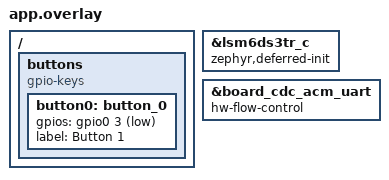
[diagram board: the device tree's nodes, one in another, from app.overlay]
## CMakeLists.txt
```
cmake_minimum_required(VERSION 3.20.0)
find_package(Zephyr REQUIRED HINTS $ENV{ZEPHYR_BASE})
project(firmware)

FILE(GLOB app_sources src/*.c)
list(FILTER app_sources EXCLUDE REGEX "/(hids_mouse|ble_gatt)\\.c$")
target_sources(app PRIVATE ${app_sources})

if(CONFIG_IM_BLE_DEVICE_MOUSE)
  target_sources(app PRIVATE src/hids_mouse.c)
endif()
if(CONFIG_IM_BLE_DEVICE_GATT)
  target_sources(app PRIVATE src/ble_gatt.c)
endif()
```

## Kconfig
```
menu "IMU Mouse"

choice IM_BLE_DEVICE
	prompt "BLE device"
	default IM_BLE_DEVICE_GATT
	help
	  Only the selected device is compiled, initialized and advertised.
config IM_BLE_DEVICE_GATT
	bool "IMU pose streaming (custom GATT service)"
config IM_BLE_DEVICE_MOUSE
	bool "HID mouse"
endchoice

choice IM_BUTTON_MODE
	prompt "Button 1 function"
	default IM_BUTTON_MODE_SENSITIVITY
	help
	  What button 1 does once the passkey pairing is not pending.
config IM_BUTTON_MODE_CLICK
	bool "Left mouse button (click and hold)"
config IM_BUTTON_MODE_SENSITIVITY
	bool "Cycle cursor sensitivity"
endchoice

config IM_IMU_SAMPLE_RATE_HZ
	int "imu update rate"
	range 52 416
	default 208
	help
		12, 26, 52, 104, 208, 416, 833, 1666, 3332 and 6664 Hz

config IM_IMU_SKIP_CALIBRATION_MOTION_CHECK
	bool "Debug: accept motion during startup gyro calibration"
		default n
	help
	  Development only. Calibration completes after a fixed sample count even if
	  the device moves (e.g. on a train); expect gyro bias drift.

config IM_IMU_PRINT_SAMPLE
	bool "Print each IMU sample"
	default n

config IM_IMU_PRINT_PERIODIC_STATS
	bool "Periodic IMU statistics"
	default n

config IM_IMU_STATS_PERIOD_MS
	int "IMU statistics period in milliseconds"
	depends on IM_IMU_PRINT_PERIODIC_STATS
	default 1000

config IM_BLE_GATT_PRINT_PERIODIC_STATS
	bool "Periodic BLE GATT statistics"
	depends on IM_BLE_DEVICE_GATT
	default n

config IM_BLE_GATT_STATS_PERIOD_MS
	int "BLE GATT statistics period in milliseconds"
	depends on IM_BLE_GATT_PRINT_PERIODIC_STATS
	default 1000
		
config SAMPLE_BT_HIDS_SECURITY
	bool "Bluetooth LE security"
	default y
	imply BT_PRIVACY
	select BT_SMP
	select BT_SETTINGS
	select FLASH
	select FLASH_PAGE_LAYOUT
	select FLASH_MAP
	select SETTINGS
	imply ZMS if (SOC_FLASH_NRF_RRAM || SOC_FLASH_NRF_MRAM)
	imply NVS if !(SOC_FLASH_NRF_RRAM || SOC_FLASH_NRF_MRAM)
	help
	  Enable Bluetooth LE security support.

config SAMPLE_BT_HIDS_SECURITY_MITM
	bool "Passkey display MITM protection"
	depends on SAMPLE_BT_HIDS_SECURITY
	depends on PRINTK
	default y
	help
	  Enable displaying passkey for Man-In-The-Middle (MITM) protection.
	  Implementation uses the "printk" function to display the passkey.

config SAMPLE_BT_DIRECTED_ADVERTISING
	bool "Directed advertising"
	default n
	depends on SAMPLE_BT_HIDS_SECURITY

endmenu

source "Kconfig.zephyr"
```

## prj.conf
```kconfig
# Logging subsystem
CONFIG_LOG=y
CONFIG_LOG_MODE_DEFERRED=y  # Log to RAM buffer
CONFIG_LOG_BUFFER_SIZE=4096
CONFIG_LOG_PROCESS_THREAD=n # Turn off log kernel thread

# USB CDC ACM - virtual serial port
CONFIG_USB_DEVICE_STACK=y

# Turn off the new USB stack
CONFIG_USB_DEVICE_STACK_NEXT=n
CONFIG_USBD_CDC_ACM_CLASS=n
CONFIG_USB_CDC_ACM_RINGBUF_SIZE=4096

# Device init logging
CONFIG_SENSOR_LOG_LEVEL_DBG=n
CONFIG_I2C_LOG_LEVEL_DBG=n

# Devices
CONFIG_I2C=y
CONFIG_SENSOR=y
CONFIG_SERIAL=y
CONFIG_UART_LINE_CTRL=y
CONFIG_LSM6DSL=y
CONFIG_LSM6DSL_TRIGGER_OWN_THREAD=y # Data-ready interrupt on irq-gpios

# Other
CONFIG_CBPRINTF_FP_SUPPORT=y

# Hardware FPU, threads using it need K_FP_REGS
CONFIG_FPU=y
CONFIG_FPU_SHARING=y

# Bluetooth setup below
CONFIG_BT=y
CONFIG_BT_MAX_CONN=1
CONFIG_BT_MAX_PAIRED=2
CONFIG_BT_ATT_TX_COUNT=16
CONFIG_BT_L2CAP_TX_BUF_COUNT=16
CONFIG_BT_BUF_ACL_TX_COUNT=16
CONFIG_BT_BUF_EVT_RX_COUNT=20
CONFIG_BT_PERIPHERAL=y
CONFIG_BT_DEVICE_NAME="IMU Sandbox"
CONFIG_BT_DEVICE_APPEARANCE=962
CONFIG_BT_L2CAP_TX_MTU=128
CONFIG_BT_BUF_ACL_TX_SIZE=70
CONFIG_BT_BUF_ACL_RX_SIZE=70

CONFIG_NCS_SAMPLES_DEFAULTS=y

# Disable automatic initiation of PHY updates and the SMP Security Requests.
# Workaround to prevent disconnection with the following disconnect reasons:
# - 0x08 (BT_HCI_ERR_CONN_TIMEOUT)
# - 0x13 (BT_HCI_ERR_REMOTE_USER_TERM_CONN)
# - 0x23 (BT_HCI_ERR_LL_PROC_COLLISION)
# - 0x2A (BT_HCI_ERR_DIFF_TRANS_COLLISION)
# Some laptop Bluetooth controllers may simultaneously trigger two Link Layer
# procedures which results in a procedure collision and disconnection.
CONFIG_BT_GATT_AUTO_SEC_REQ=n
CONFIG_BT_AUTO_PHY_UPDATE=n

CONFIG_BT_BAS=y
CONFIG_BT_HIDS=y
CONFIG_BT_HIDS_INPUT_REP_MAX=3
CONFIG_BT_HIDS_OUTPUT_REP_MAX=0
CONFIG_BT_HIDS_FEATURE_REP_MAX=0
CONFIG_BT_HIDS_ATTR_MAX=24
CONFIG_BT_HIDS_MAX_CLIENT_COUNT=1
CONFIG_BT_HIDS_DEFAULT_PERM_RW_ENCRYPT=y
CONFIG_BT_GATT_UUID16_POOL_SIZE=40
CONFIG_BT_GATT_CHRC_POOL_SIZE=20

CONFIG_BT_CONN_CTX=y

CONFIG_BT_DIS=y
CONFIG_BT_DIS_MANUF_NAME=y
CONFIG_BT_DIS_MANUF_NAME_STR="NordicSemiconductor"
CONFIG_BT_DIS_PNP=y
CONFIG_BT_DIS_PNP_VID_SRC=2
CONFIG_BT_DIS_PNP_VID=0x1915
CONFIG_BT_DIS_PNP_PID=0xEEEE
CONFIG_BT_DIS_PNP_VER=0x0100

# Increase BT TX processor thread stack size to prevent stack overflow when performing directed
# advertising. On nRF52840 the maximum measured stack usage is 780 bytes. On nRF54L15 the maximum
# measured stack usage is 856 bytes.
CONFIG_BT_TX_PROCESSOR_STACK_SIZE=1024

CONFIG_MAIN_STACK_SIZE=2048
CONFIG_SYSTEM_WORKQUEUE_STACK_SIZE=2048

# Delay the GATT/ATT "sent" callback until the controller has actually transmitted the PDU,
# instead of firing it as soon as the buffer is handed to L2CAP/HCI.
# The movement in-flight limit in hids_mouse.c relies on this.
CONFIG_BT_ATT_SENT_CB_AFTER_TX=y
```

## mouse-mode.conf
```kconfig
CONFIG_IM_BLE_DEVICE_MOUSE=y
```

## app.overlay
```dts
&lsm6ds3tr_c {
	// Skip boot-time init (timing issue):
	// 	<dbg> LSM6DSL: lsm6dsl_init_chip: failed to reboot device
	// 	<err> LSM6DSL: Failed to initialize chip
	// im_imu_init() calls device_init() later
	zephyr,deferred-init;
};

&board_cdc_acm_uart {
	// Without it poll_out drops data when the 1 KB TX ring buffer is full, losing early logs
	hw-flow-control;
};

#include <zephyr/dt-bindings/gpio/gpio.h>

/ {
    buttons {
        compatible = "gpio-keys";

        button0: button_0 {
            gpios = <&gpio0 3 (GPIO_PULL_UP | GPIO_ACTIVE_LOW)>;  // Button D1 of the Seeed Studio XIAO Expansion Board
            label = "Button 1";
        };
    };
};
```

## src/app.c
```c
#include <stdio.h>
#include <math.h>
#include <zephyr/kernel.h>

#include "state.h"
#include "imu.h"
#include "fusion.h"
#include "gpio.h"

#if defined(CONFIG_IM_BLE_DEVICE_MOUSE)
#include "hids_mouse.h"

// Integers on purpose: level 2 (2500) is the default
static const int s_px_per_rad[] = {1500, 2000, 2500, 3000, 3500, 4000, 4500, 5000, 5500};
static uint8_t s_sens_idx = 2;
// Mounting-dependent: yaw (gyro Z) -> X, pitch (gyro Y) -> Y; roll (gyro X) is ignored
#define MOUSE_X_SIGN (-1.0f)
#define MOUSE_Y_SIGN (-1.0f) // Cable to front
#define MOUSE_DEADZONE_RAD_S 0.02f

// Sub-pixel remainders carried between samples
static float s_mouse_rem_x;
static float s_mouse_rem_y;

// A press that confirmed pairing must not produce a click release
static bool s_press_used_for_pairing;
#elif defined(CONFIG_IM_BLE_DEVICE_GATT)
#include "ble_gatt.h"
#endif

static atomic_t s_streaming_active;

void im_app_on_error(void)
{
	im_state_set(IM_APP_STATE_FAIL);
}

void im_app_on_ble_session(bool ready)
{
	const atomic_val_t new_state = ready ? 1 : 0;
	const atomic_val_t old_state = atomic_set(&s_streaming_active, new_state);
	if (old_state == new_state)
	{
		return;
	}
	im_state_set(ready ? IM_APP_STATE_CALIBRATING : IM_APP_STATE_WAITING);
	im_imu_set_streaming(ready);
}

void im_app_on_button(bool pressed)
{
#if defined(CONFIG_IM_BLE_DEVICE_MOUSE)
	if (pressed && im_hids_mouse_pairing_pending())
	{
		s_press_used_for_pairing = true;
		im_hids_mouse_pairing_reply(true);
		return;
	}
	if (!pressed && s_press_used_for_pairing)
	{
		s_press_used_for_pairing = false;
		return;
	}
	if (IS_ENABLED(CONFIG_IM_BUTTON_MODE_SENSITIVITY))
	{
		if (pressed)
		{
			s_sens_idx = (s_sens_idx + 1) % ARRAY_SIZE(s_px_per_rad);
			printk("Sensitivity: %d px/rad\n", s_px_per_rad[s_sens_idx]);
		}
	}
	else if(IS_ENABLED(CONFIG_IM_BUTTON_MODE_CLICK))
	{
		im_hids_mouse_button(pressed);
	}
#elif defined(CONFIG_IM_BLE_DEVICE_GATT)
	ARG_UNUSED(pressed);
#endif
}

void im_app_on_imu_sample(im_vec3 gyro_rate, im_vec3 acceleration, float dt_s)
{
	enum im_app_state state = im_state_get();
	if (state != IM_APP_STATE_CALIBRATING && state != IM_APP_STATE_RUNNING)
	{
		return;
	}

	struct im_fusion_rates rates;
	const bool fusion_valid = im_fusion_update(gyro_rate, acceleration, dt_s, &rates);
	if (!fusion_valid)
	{
		return;
	}
	if (state == IM_APP_STATE_CALIBRATING)
	{
		im_state_set(IM_APP_STATE_RUNNING);
	}

#if defined(CONFIG_IM_BLE_DEVICE_MOUSE)
	const float px_per_rad = (float)s_px_per_rad[s_sens_idx];
	const bool x_active = fabsf(rates.yaw) >= MOUSE_DEADZONE_RAD_S;
	const bool y_active = fabsf(rates.pitch) >= MOUSE_DEADZONE_RAD_S;
	const float fx = x_active
		? s_mouse_rem_x + MOUSE_X_SIGN * rates.yaw * px_per_rad * dt_s
		: 0.0f;
	const float fy = y_active
		? s_mouse_rem_y + MOUSE_Y_SIGN * rates.pitch * px_per_rad * dt_s
		: 0.0f;
	const int16_t dx = (int16_t)fx;
	const int16_t dy = (int16_t)fy;
	s_mouse_rem_x = x_active ? fx - dx : 0.0f;
	s_mouse_rem_y = y_active ? fy - dy : 0.0f;
	if (dx || dy)
	{
		im_hids_mouse_move(dx, dy);
	}
#elif defined(CONFIG_IM_BLE_DEVICE_GATT)
	im_ble_gatt_push_frame(rates.orientation, acceleration);
#endif
}
```

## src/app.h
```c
#ifndef IM_APP_H
#define IM_APP_H

#include <stdbool.h>
#include "math3d.h"

// Application events
void im_app_on_imu_sample(im_vec3 gyro_rate, im_vec3 acceleration, float dt_s);
void im_app_on_error(void);
void im_app_on_ble_session(bool ready);
void im_app_on_button(bool pressed);

#endif
```

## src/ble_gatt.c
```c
#include <math.h>
#include <stdint.h>
#include <errno.h>
#include <string.h>

#include <zephyr/kernel.h>
#include <zephyr/sys/byteorder.h>
#include <zephyr/sys/printk.h>
#include <zephyr/bluetooth/bluetooth.h>
#include <zephyr/bluetooth/gatt.h>
#include <zephyr/bluetooth/uuid.h>
#include <zephyr/settings/settings.h>

#include "ble_gatt.h"
#include "threads.h"

// Internal linkage

// Thread and synchronisation
static K_THREAD_STACK_DEFINE(s_ble_gatt_thread_stack, IM_BLE_GATT_THREAD_STACK_SIZE);
static struct k_thread s_ble_gatt_thread_data;
static K_SEM_DEFINE(s_pending_frame_ready, 0, 1);

// Latest encoded frame; a newer pose overwrites an unsent one
#define BLE_POSE_FRAME_SIZE 20
static bool s_pending;
static struct k_spinlock s_pending_lock;
static uint8_t s_pending_frame[BLE_POSE_FRAME_SIZE];
static uint16_t s_frame_sequence;
static bool s_link_connected;
static bool s_pose_notifications_enabled;
static volatile uint16_t s_connection_interval;
static im_ble_gatt_session_cb_t s_session_callback;

/* Connection intervals are expressed in 1.25 ms units. */
#define MIN_SEND_INTERVAL_UNITS 6
#define MAX_SEND_INTERVAL_UNITS 9

static void s_update_streaming(void)
{
	const bool fast_enough = s_connection_interval >= MIN_SEND_INTERVAL_UNITS && s_connection_interval <= MAX_SEND_INTERVAL_UNITS;
	const bool ready = s_link_connected && s_pose_notifications_enabled && fast_enough;
	if (!ready)
	{
		k_spinlock_key_t key = k_spin_lock(&s_pending_lock);
		s_pending = false;
		k_spin_unlock(&s_pending_lock, key);
	}
	if (s_session_callback)
	{
		s_session_callback(ready);
	}
}

// Diagnostics, printed once per second
static uint32_t s_stat_ok, s_stat_err, s_stat_max_us, s_stat_dropped, s_stat_gated;
static int s_stat_last_err;
#if CONFIG_IM_BLE_GATT_PRINT_PERIODIC_STATS
static int64_t s_stat_next_ms;
#endif

// Service definition
// UUIDs match simulator/src/ble/ble-client.ts and docs/ble.md.
#define BLE_SERVICE_UUID_BYTES 0x9e, 0xca, 0xcc, 0x24, 0x0e, 0xe5, 0xa9, 0xe0, 0x93, 0xf3, 0xa3, 0xb5, 0x01, 0x00, 0x40, 0x7e
#define BLE_POSE_UUID_BYTES 0x9e, 0xca, 0xcc, 0x24, 0x0e, 0xe5, 0xa9, 0xe0, 0x93, 0xf3, 0xa3, 0xb5, 0x02, 0x00, 0x40, 0x7e
#define BLE_INFO_UUID_BYTES 0x9e, 0xca, 0xcc, 0x24, 0x0e, 0xe5, 0xa9, 0xe0, 0x93, 0xf3, 0xa3, 0xb5, 0x03, 0x00, 0x40, 0x7e
static struct bt_uuid_128 s_service_uuid = BT_UUID_INIT_128(BLE_SERVICE_UUID_BYTES);
static struct bt_uuid_128 s_pose_uuid = BT_UUID_INIT_128(BLE_POSE_UUID_BYTES);
static struct bt_uuid_128 s_info_uuid = BT_UUID_INIT_128(BLE_INFO_UUID_BYTES);

static void s_pose_ccc_changed(const struct bt_gatt_attr *attr, uint16_t value)
{
	// Client Characteristic Configuration Descriptor (CCCD)
	// Notifications enabled means that a client subscribed to the service
	// This is only informational
	ARG_UNUSED(attr);
	s_pose_notifications_enabled = (value & BT_GATT_CCC_NOTIFY) != 0;
	s_update_streaming();
	if (s_pose_notifications_enabled)
	{
		printk("BLE GATT pose notifications enabled\n");
	}
	else
	{
		printk("BLE GATT pose notifications disabled\n");
	}
}
static ssize_t s_read_info(struct bt_conn *conn, const struct bt_gatt_attr *attr, void *buf, uint16_t len, uint16_t offset)
{
	ARG_UNUSED(attr);
	const uint8_t info[] = 
	{
		CONFIG_IM_IMU_SAMPLE_RATE_HZ & 0xff,
		(CONFIG_IM_IMU_SAMPLE_RATE_HZ >> 8) & 0xff,
	};
	return bt_gatt_attr_read(conn, attr, buf, len, offset, info, sizeof(info));
}
BT_GATT_SERVICE_DEFINE(ble_gatt_service,
	BT_GATT_PRIMARY_SERVICE(&s_service_uuid),
	BT_GATT_CHARACTERISTIC(&s_pose_uuid.uuid, BT_GATT_CHRC_NOTIFY, BT_GATT_PERM_NONE, NULL, NULL, NULL),
	BT_GATT_CCC(s_pose_ccc_changed, BT_GATT_PERM_READ | BT_GATT_PERM_WRITE),
	BT_GATT_CHARACTERISTIC(&s_info_uuid.uuid, BT_GATT_CHRC_READ, BT_GATT_PERM_READ, s_read_info, NULL, NULL),
);

// Advertisement
static struct k_work s_adv_work;
static const struct bt_data s_ad[] =
{
	BT_DATA_BYTES(BT_DATA_FLAGS, (BT_LE_AD_GENERAL | BT_LE_AD_NO_BREDR)),
	BT_DATA_BYTES(BT_DATA_UUID128_ALL, BLE_SERVICE_UUID_BYTES),
};
static const struct bt_data s_sd[] =
{
	BT_DATA(BT_DATA_NAME_COMPLETE, CONFIG_BT_DEVICE_NAME, sizeof(CONFIG_BT_DEVICE_NAME) - 1),
};
static void s_adv_process(struct k_work *work)
{
	ARG_UNUSED(work);
	const int err = bt_le_adv_start(BT_LE_ADV_CONN_FAST_2, s_ad, ARRAY_SIZE(s_ad), s_sd, ARRAY_SIZE(s_sd));
	if (err)
	{
		printk("ERROR: BLE GATT advertising failed to start (err %d)\n", err);
		return;
	}
	printk("BLE GATT advertising started\n");
}

// Connection lifecycle and timing
// Requested connection interval 7.5-11.25 ms, latency 0, 4s timeout.
#define FAST_CONN_PARAM BT_LE_CONN_PARAM(MIN_SEND_INTERVAL_UNITS, MAX_SEND_INTERVAL_UNITS, 0, 400)
static void s_connected(struct bt_conn *conn, uint8_t err)
{
	if (err)
	{
		s_link_connected = false;
		s_pose_notifications_enabled = false;
		s_update_streaming();
		printk("Error: BLE GATT connection failed (err 0x%02x)\n", err);
		k_work_submit(&s_adv_work);
		return;
	}
	s_link_connected = true;
	s_connection_interval = 0;
	// Reads the interval when connection starts
	// Interval is set by the central, peripherial can request different interval later
	struct bt_conn_info info;
	if (bt_conn_get_info(conn, &info) == 0)
	{
		s_connection_interval = info.le.interval;
		printk("BLE GATT connection begin: interval=%u\n", s_connection_interval);
	}
	s_update_streaming();
	const int param_err = bt_conn_le_param_update(conn, FAST_CONN_PARAM);
	if (param_err)
	{
		printk("Error: BLE GATT connection parameter update request failed (err %d)\n", param_err);
	}
}
static void s_disconnected(struct bt_conn *conn, uint8_t reason)
{
	ARG_UNUSED(conn);
	ARG_UNUSED(reason);
	s_link_connected = false;
	s_pose_notifications_enabled = false;
	s_connection_interval = 0;
	s_update_streaming();
	printk("BLE GATT connection end\n");
	k_work_submit(&s_adv_work);
}
static void s_le_param_updated(struct bt_conn *conn, uint16_t interval, uint16_t latency, uint16_t timeout)
{
	// This is called when the central accepts new interval values
	ARG_UNUSED(conn);
	printk("BLE GATT connection params: interval=%u (%u.%02u ms) latency=%u timeout=%u\n", interval, interval * 5 / 4, (interval * 125) % 100, latency, timeout);
	s_connection_interval = interval;
	s_update_streaming();
}
BT_CONN_CB_DEFINE(s_connection_cb) =
{
	.connected = s_connected,
	.disconnected = s_disconnected,
	.le_param_updated = s_le_param_updated,
};

static void s_ble_gatt_thread_fn(void *p1, void *p2, void *p3)
{
	ARG_UNUSED(p1);
	ARG_UNUSED(p2);
	ARG_UNUSED(p3);
	while (1)
	{
		k_sem_take(&s_pending_frame_ready, K_FOREVER);

		// Copy frame from pending buffer
		uint8_t frame[BLE_POSE_FRAME_SIZE];
		k_spinlock_key_t key = k_spin_lock(&s_pending_lock);
		const bool have = s_pending;
		if (have)
		{
			memcpy(frame, s_pending_frame, sizeof(frame));
			s_pending = false;
		}
		k_spin_unlock(&s_pending_lock, key);
		// Send the local frame
		if (have)
		{
			const uint32_t t0 = k_cycle_get_32();
			const int err = bt_gatt_notify(NULL, &ble_gatt_service.attrs[2], frame, sizeof(frame));
			const uint32_t dt_us = k_cyc_to_us_floor32(k_cycle_get_32() - t0);
			if (dt_us > s_stat_max_us)
			{
				s_stat_max_us = dt_us;
			}
			if (err == 0)
			{
				s_stat_ok++;
			}
			else if (err != -ENOTCONN)
			{
				s_stat_err++;
				s_stat_last_err = err;
			}
		}
#if CONFIG_IM_BLE_GATT_PRINT_PERIODIC_STATS
		const int64_t now_ms = k_uptime_get();
		if (have && now_ms >= s_stat_next_ms)
		{
			printk("BLE GATT notify: ok=%u err=%u (last %d) dropped=%u gated=%u max_call=%u us\n", s_stat_ok, s_stat_err, s_stat_last_err, s_stat_dropped, s_stat_gated, s_stat_max_us);
			s_stat_ok = s_stat_err = s_stat_max_us = s_stat_dropped = s_stat_gated = 0;
			s_stat_next_ms = now_ms + CONFIG_IM_BLE_GATT_STATS_PERIOD_MS;
		}
#endif
	}
}

static int16_t s_clamp_i16(float value)
{
	if (value > INT16_MAX)
	{
		return INT16_MAX;
	}
	if (value < INT16_MIN)
	{
		return INT16_MIN;
	}
	return (int16_t)lrintf(value);
}

// External linkage

bool im_ble_gatt_init(void)
{
	printk("BLE GATT initiating\n");
	const int err = bt_enable(NULL);
	if (err)
	{
		printk("BLE GATT init failed (err %d)\n", err);
		return false;
	}
	k_work_init(&s_adv_work, s_adv_process);
	if (IS_ENABLED(CONFIG_SETTINGS))
	{
		settings_load();
	}
	printk("BLE GATT initialized\n");
	return true;
}

void im_ble_gatt_set_session_callback(im_ble_gatt_session_cb_t callback)
{
	s_session_callback = callback;
	s_update_streaming();
}

bool im_ble_gatt_start(void)
{
	k_tid_t tid = k_thread_create(&s_ble_gatt_thread_data, s_ble_gatt_thread_stack,
					      K_THREAD_STACK_SIZEOF(s_ble_gatt_thread_stack),
					      s_ble_gatt_thread_fn, NULL, NULL, NULL,
					      IM_BLE_GATT_THREAD_PRIORITY, 0, K_NO_WAIT);
	if (!tid)
	{
		printk("Error: BLE GATT thread failed to start\n");
		return false;
	}
	k_thread_name_set(tid, "ble_gatt");
	k_work_submit(&s_adv_work);	// This begins the advertisement
	printk("BLE GATT started\n");
	return true;
}

bool im_ble_gatt_push_frame(im_quat orientation, im_vec3 acceleration)
{
	// Gate poses to honor the agreed interval
	const uint16_t interval = s_connection_interval;
	if (!s_link_connected || !s_pose_notifications_enabled || interval == 0 ||
	    interval > MAX_SEND_INTERVAL_UNITS)
	{
		s_stat_gated++;
		return false;
	}

	// Build the frame
	uint8_t frame[BLE_POSE_FRAME_SIZE] = {0};
	sys_put_le16(s_frame_sequence++, &frame[0]);
	sys_put_le32(k_uptime_get_32(), &frame[2]);
	sys_put_le16(s_clamp_i16(orientation.w * 16384.0f), &frame[6]);
	sys_put_le16(s_clamp_i16(orientation.x * 16384.0f), &frame[8]);
	sys_put_le16(s_clamp_i16(orientation.y * 16384.0f), &frame[10]);
	sys_put_le16(s_clamp_i16(orientation.z * 16384.0f), &frame[12]);
	// Acceleration is m/s^2 internally; the wire unit is 1 mg (0.001 g).
	sys_put_le16(s_clamp_i16(acceleration.x * 101.9716f), &frame[14]);
	sys_put_le16(s_clamp_i16(acceleration.y * 101.9716f), &frame[16]);
	sys_put_le16(s_clamp_i16(acceleration.z * 101.9716f), &frame[18]);

	// Signal the thread but only if it processed previous frame
	// Otherwise, update the pending frame - last frame will be sent
	k_spinlock_key_t key = k_spin_lock(&s_pending_lock);
	if (s_pending)
	{
		s_stat_dropped++;
	}
	memcpy(s_pending_frame, frame, sizeof(frame));
	s_pending = true;
	k_spin_unlock(&s_pending_lock, key);
	k_sem_give(&s_pending_frame_ready);
	return true;
}
```

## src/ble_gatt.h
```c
#ifndef IM_BLE_GATT_H
#define IM_BLE_GATT_H

#include <stdbool.h>
#include "math3d.h"

typedef void (*im_ble_gatt_session_cb_t)(bool ready);

bool im_ble_gatt_init(void);
bool im_ble_gatt_start(void);
void im_ble_gatt_set_session_callback(im_ble_gatt_session_cb_t callback);

// acceleration is body-frame specific force in m/s^2 (gravity included).
// Returns true when queued; replaces an older pending frame if one has not been sent. */
bool im_ble_gatt_push_frame(im_quat orientation, im_vec3 acceleration);

#endif
```

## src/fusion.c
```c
#include <math.h>
#include <zephyr/kernel.h>
#include <zephyr/sys/printk.h>

#include "fusion.h"
#include "imu.h"
#include "math3d.h"

/*
 * Sensor fusion: gyro + accelerometer -> yaw/pitch rates for the cursor.
 *
 * Orientation is a unit quaternion integrated from the gyro and corrected by the accelerometer
 * (Mahony complementary filter, proportional term only):
 *   - The gyro is smooth and precise short-term, but its bias makes the angle drift.
 *   - The accelerometer measures gravity, which gives an absolute tilt (roll/pitch), but is
 *     noisy and wrong while the device accelerates. It is trusted only when |a| is close to 1 g.
 *   - The error between measured and estimated "up" (cross product) is fed back into the gyro
 *     rate with gain FUSION_KP, which pulls the tilt estimate toward gravity.
 *   - Gravity says nothing about yaw, so yaw is gyro-only; its drift is limited by bias removal.
 *
 * Gyro bias is removed in two steps: an averaged startup calibration (device must lie still),
 * then a slow low-pass update while the device is detected as stationary. Rates under a small
 * deadzone are zeroed while stationary so the cursor does not creep.
 *
 * The output rates are taken about gravity (yaw) and about the horizontal part of body Y (pitch),
 * so the cursor motion does not depend on how the device is rolled.
 *
 * Sensor axes (device in hand with USB port pointing forward), based on stationary measurements:
 * - X-axis: Longitudinally along the board. Positive value away from the USB port.
 * - Y-axis: Laterally across the board. Positive value towards the right side.
 * - Z-axis: Perpendicular to the board. Positive value points up when the board lies flat.
 *
 * Positive rotations follow the right-hand rule:
 * - Roll about +X: +Y rotates toward +Z.
 * - Pitch about +Y: +Z rotates toward +X.
 * - Yaw about +Z: +X rotates toward +Y.
 *
 * TOP VIEW
 *                USB PORT
 *                forward ^
 *                        |
 *             +------------------+
 *             |                  |----> +Y (right)
 *             |      DEVICE      |
 *             |                  |
 *             +------------------+
 *                        |
 *                        v
 *                 +X (away from USB)
 *
 *     +Z points up, toward the viewer.
 */

#define GRAVITY 9.80665f
// Mahony proportional gain (rad/s per unit error): higher trusts the accelerometer more
#define FUSION_KP 1.0f
// Accelerometer is used for tilt correction only while |a| is within this of 1 g
#define ACCEL_TRUST_TOL (0.1f * GRAVITY)
// Device counts as stationary when the bias-corrected gyro is below this
#define STILL_GYRO_RAD_S 0.03f
#define STILL_ACCEL_TOL (0.05f * GRAVITY)
#define STILL_SAMPLES (CONFIG_IM_IMU_SAMPLE_RATE_HZ / 4)
#define BIAS_ALPHA 0.002f
// Output rates below this while stationary are suppressed
#define STILL_DEADZONE_RAD_S 0.004f
// Startup calibration: average this many still samples; any motion restarts it
#define CAL_SAMPLES CONFIG_IM_IMU_SAMPLE_RATE_HZ
#define CAL_MOTION_RAD_S 0.05f

static bool s_cal_done;
static uint32_t s_cal_count;
static im_vec3 s_cal_sum;
// Orientation (body to world), gravity-referenced; yaw is gyro-only
static im_quat s_orientation = {1.0f, 0.0f, 0.0f, 0.0f};
static bool s_q_init;
static im_vec3 s_bias;
static uint32_t s_still_count;

void im_fusion_reset(void)
{
	s_cal_done = false;
	s_cal_count = 0;
	s_cal_sum = (im_vec3){0.0f, 0.0f, 0.0f};
	s_orientation = im_quat_identity();
	s_q_init = false;
	s_bias = (im_vec3){0.0f, 0.0f, 0.0f};
	s_still_count = 0;
}

static void s_init_from_accel(im_vec3 measured_up)
{
	if (!im_vec3_normalize(&measured_up))
	{
		return;
	}
	const im_vec3 world_up = {0.0f, 0.0f, 1.0f};
	s_orientation = im_quat_from_unit_vectors(measured_up, world_up);
	s_q_init = true;
}

static im_vec3 s_get_up_in_body(void)
{
	const im_vec3 world_up = {0.0f, 0.0f, 1.0f};
	return im_quat_rotate_inverse(s_orientation, world_up);
}

// Gyro in rad/s (bias removed), accel in m/s^2, elapsed time in seconds
static void s_update_orientation(im_vec3 gyro_rate, im_vec3 acceleration, float a_norm, float dt_s)
{
	if (fabsf(a_norm - GRAVITY) < ACCEL_TRUST_TOL)
	{
		im_vec3 measured_up = acceleration;
		im_vec3_normalize(&measured_up);
		const im_vec3 estimated_up = s_get_up_in_body();
		const im_vec3 error = im_vec3_cross(measured_up, estimated_up);
		gyro_rate = im_vec3_add(gyro_rate, im_vec3_scale(error, FUSION_KP));
	}
	const float h = 0.5f * dt_s;
	const im_quat angular_rate = {0.0f, gyro_rate.x, gyro_rate.y, gyro_rate.z};
	const im_quat derivative = im_quat_multiply(s_orientation, angular_rate);
	s_orientation = im_quat_add(s_orientation, im_quat_scale(derivative, h));
	if (!im_quat_normalize(&s_orientation))
	{
		s_orientation = im_quat_identity();
	}
}

static void s_update_calibration(im_vec3 gyro_rate)
{
	/* This variation-only check can mistake steady rotation for gyro bias. */
#ifndef CONFIG_IM_IMU_SKIP_CALIBRATION_MOTION_CHECK
	if (s_cal_count > 0)
	{
		const im_vec3 mean = im_vec3_scale(s_cal_sum, 1.0f / s_cal_count);
		const im_vec3 deviation = im_vec3_subtract(gyro_rate, mean);
		if (fabsf(deviation.x) > CAL_MOTION_RAD_S
			|| fabsf(deviation.y) > CAL_MOTION_RAD_S
			|| fabsf(deviation.z) > CAL_MOTION_RAD_S)
		{
			s_cal_count = 0;
			s_cal_sum = (im_vec3){0.0f, 0.0f, 0.0f};
		}
	}
#endif
	s_cal_sum = im_vec3_add(s_cal_sum, gyro_rate);
	if (++s_cal_count >= CAL_SAMPLES)
	{
		s_bias = im_vec3_scale(s_cal_sum, 1.0f / s_cal_count);
		s_cal_done = true;
		printk("IMU fusion calibration complete\n");
	}
}

bool im_fusion_update(im_vec3 gyro_rate, im_vec3 acceleration, float dt_s, struct im_fusion_rates *out)
{
	const float a_norm = im_vec3_length(acceleration);
	if (!s_q_init)
	{
		s_init_from_accel(acceleration);
	}

	// Initial bias calibration: device must lie still for CAL_SAMPLES
	if (!s_cal_done)
	{
		s_update_calibration(gyro_rate);
		return false;
	}

	// Gyro bias: track the raw gyro while the device is held still
	const im_vec3 corrected_rate = im_vec3_subtract(gyro_rate, s_bias);
	const bool still = fabsf(corrected_rate.x) < STILL_GYRO_RAD_S &&
			   fabsf(corrected_rate.y) < STILL_GYRO_RAD_S &&
			   fabsf(corrected_rate.z) < STILL_GYRO_RAD_S &&
			   fabsf(a_norm - GRAVITY) < STILL_ACCEL_TOL;
	s_still_count = still ? s_still_count + 1 : 0;
	const bool settled = s_still_count >= STILL_SAMPLES;
	if (settled)
	{
		float bias_alpha = BIAS_ALPHA * dt_s * CONFIG_IM_IMU_SAMPLE_RATE_HZ;
		if (bias_alpha > 1.0f)
		{
			bias_alpha = 1.0f;
		}
		s_bias = im_vec3_add(s_bias, im_vec3_scale(im_vec3_subtract(gyro_rate, s_bias), bias_alpha));
	}

	s_update_orientation(corrected_rate, acceleration, a_norm, dt_s);

	// Rates about gravity (yaw) and about the horizontal part of body Y (pitch): independent of roll
	const im_vec3 up_in_body = s_get_up_in_body();
	float yaw_rate = im_vec3_dot(corrected_rate, up_in_body);
	const im_vec3 body_y = {0.0f, 1.0f, 0.0f};
	const im_vec3 pitch_axis = im_vec3_subtract(body_y, im_vec3_scale(up_in_body, im_vec3_dot(body_y, up_in_body)));
	const float pitch_norm = im_vec3_length(pitch_axis);
	float pitch_rate = corrected_rate.y;
	if (pitch_norm > 0.2f) // near vertical the axis is ill-defined; fall back to raw Y
	{
		pitch_rate = im_vec3_dot(corrected_rate, im_vec3_scale(pitch_axis, 1.0f / pitch_norm));
	}
	if (settled && fabsf(yaw_rate) < STILL_DEADZONE_RAD_S)
	{
		yaw_rate = 0.0f;
	}
	if (settled && fabsf(pitch_rate) < STILL_DEADZONE_RAD_S)
	{
		pitch_rate = 0.0f;
	}
	out->yaw = yaw_rate;
	out->pitch = pitch_rate;
	out->orientation = s_orientation;
	out->gyro_rate = corrected_rate;
	return true;
}
```

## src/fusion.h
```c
#ifndef IM_FUSION_H
#define IM_FUSION_H

#include <stdbool.h>
#include "math3d.h"

struct im_fusion_rates
{
	float yaw;   // rad/s about gravity
	float pitch; // rad/s about the horizontal part of body Y
	im_quat orientation;
	im_vec3 gyro_rate; // bias-corrected body rate, rad/s
};

void im_fusion_reset(void);

// Feeds one sample (gyro rad/s, accel m/s^2, elapsed time in seconds).
// Returns false while the startup bias calibration runs.
bool im_fusion_update(im_vec3 gyro_rate, im_vec3 acceleration, float dt_s, struct im_fusion_rates *out);

#endif
```

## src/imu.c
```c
#include <stdio.h>
#include <zephyr/kernel.h>
#include <zephyr/device.h>
#include <zephyr/drivers/sensor.h>
#include <zephyr/drivers/i2c.h>
#include <zephyr/drivers/gpio.h>

#include "fusion.h"
#include "imu.h"
#include "state.h"
#include "threads.h"

#define IMU_REG_WHO_AM_I 0x0F

// Internal linkage

// Thread and synchronisation
static K_THREAD_STACK_DEFINE(s_imu_thread_stack, IM_IMU_THREAD_STACK_SIZE);
static struct k_thread s_imu_thread_data;
static K_SEM_DEFINE(s_imu_data_ready, 0, 1);

// Streaming state desired state
static atomic_t s_streaming_requested;

// Measurement statistics
#define IMU_READY_TIMEOUT_MS 2000
#define IMU_READY_POLL_MS 5
#define IMU_WATCHDOG_MS 50

#if CONFIG_IM_IMU_PRINT_PERIODIC_STATS
static atomic_t s_sample_count; 		// Successfully collected samples
static atomic_t s_data_ready_count; 	// Data-ready interrupts, incremented by the ISR
static int64_t s_next_report_ms;
static atomic_t s_not_acquired_count; 	// Semaphore timeouts, when samples don't arrive
#endif

// Measurement data
static struct sensor_value s_accel[3];
static struct sensor_value s_gyro[3];
static uint32_t s_last_sample_cycles;
static bool s_sample_time_valid;
static im_imu_sample_cb_t s_sample_cb;
static im_imu_error_cb_t s_error_cb;

// Hardware
static const struct device* const s_imu = DEVICE_DT_GET_ONE(st_lsm6dsl);
static const struct i2c_dt_spec s_i2c_bus = I2C_DT_SPEC_GET(DT_NODELABEL(lsm6ds3tr_c));

static bool s_imu_set_sampling_frequency(uint16_t frequency_hz)
{
	const struct sensor_value odr = { .val1 = frequency_hz, .val2 = 0 };
	if (sensor_attr_set(s_imu, SENSOR_CHAN_ACCEL_XYZ, SENSOR_ATTR_SAMPLING_FREQUENCY, &odr) < 0)
	{
		printk("Error: IMU failed to set accelerometer ODR to %u Hz\n", frequency_hz);
		return false;
	}
	if (sensor_attr_set(s_imu, SENSOR_CHAN_GYRO_XYZ, SENSOR_ATTR_SAMPLING_FREQUENCY, &odr) < 0)
	{
		printk("Error: IMU failed to set gyroscope ODR to %u Hz\n", frequency_hz);
		return false;
	}
	return true;
}
// IMU data-ready interrupt
static void s_imu_data_ready_handler(const struct device *dev, const struct sensor_trigger *trig)
{
	ARG_UNUSED(dev);
	ARG_UNUSED(trig);
#if CONFIG_IM_IMU_PRINT_PERIODIC_STATS
	atomic_inc(&s_data_ready_count);
#endif
	k_sem_give(&s_imu_data_ready);
}

bool s_imu_collect()
{
	// I2C moves data to driver memory, clears the interrupt
	if (sensor_sample_fetch(s_imu) < 0)
	{
		printk("Error: IMU Sensor sample update error\n");
		return false;
	}
	const uint32_t sample_cycles = k_cycle_get_32();
	float dt_s = 0.0f;
	if (s_sample_time_valid)
	{
		const uint32_t elapsed_cycles = sample_cycles - s_last_sample_cycles;
		dt_s = (float)k_cyc_to_us_floor64(elapsed_cycles) * 1e-6f;
	}
	s_last_sample_cycles = sample_cycles;
	s_sample_time_valid = true;
	sensor_channel_get(s_imu, SENSOR_CHAN_ACCEL_XYZ, s_accel);
	sensor_channel_get(s_imu, SENSOR_CHAN_GYRO_XYZ, s_gyro);
	const im_vec3 gyro_rate = {
		sensor_value_to_float(&s_gyro[0]),
		sensor_value_to_float(&s_gyro[1]),
		sensor_value_to_float(&s_gyro[2]),
	};
	const im_vec3 acceleration = {
		sensor_value_to_float(&s_accel[0]),
		sensor_value_to_float(&s_accel[1]),
		sensor_value_to_float(&s_accel[2]),
	};
	// Notify callback
	if (s_sample_cb)
	{
		s_sample_cb(gyro_rate, acceleration, dt_s);
	}
#if CONFIG_IM_IMU_PRINT_SAMPLE
	char out_str[64];
	sprintf(out_str, "accel x:%f ms/2 y:%f ms/2 z:%f ms/2", sensor_value_to_float(&s_accel[0]), sensor_value_to_float(&s_accel[1]), sensor_value_to_float(&s_accel[2]));
	printk("%s\n", out_str);
	sprintf(out_str, "gyro x:%f dps y:%f dps z:%f dps", sensor_value_to_float(&s_gyro[0]), sensor_value_to_float(&s_gyro[1]), sensor_value_to_float(&s_gyro[2]));
	printk("%s\n", out_str);
#endif
	return true;
}

static void s_imu_thread_fn(void *p1, void *p2, void *p3)
{
	ARG_UNUSED(p1);
	ARG_UNUSED(p2);
	ARG_UNUSED(p3);
	bool streaming = false;
	while (1)
	{
		if (!streaming)
		{
			k_sem_take(&s_imu_data_ready, K_FOREVER);
			if (!atomic_get(&s_streaming_requested))
			{
				continue;
			}

			// Start streaming after the request wakes the idle thread.
			k_sem_reset(&s_imu_data_ready);
			if (!s_imu_set_sampling_frequency(CONFIG_IM_IMU_SAMPLE_RATE_HZ))
			{
				if (s_error_cb) s_error_cb();
				return;
			}
			streaming = true;
			s_sample_time_valid = false;
			im_fusion_reset();
			continue;
		}
		const bool acquired = k_sem_take(&s_imu_data_ready, K_MSEC(IMU_WATCHDOG_MS)) == 0;
		if (!atomic_get(&s_streaming_requested))
		{
			// Stop before collecting another sample.
			if (!s_imu_set_sampling_frequency(0))
			{
				if (s_error_cb) s_error_cb();
				return;
			}
			streaming = false;
			s_sample_time_valid = false;
			continue;
		}

		// The watchdog read can recover a sample if the interrupt edge was missed.
#if CONFIG_IM_IMU_PRINT_PERIODIC_STATS
		if (!acquired)
		{
			atomic_inc(&s_not_acquired_count);
		}
#else
		ARG_UNUSED(acquired);
#endif
		if (!s_imu_collect())
		{
			if (s_error_cb) s_error_cb();
			return;
		}
		// Statistics reporting
#if CONFIG_IM_IMU_PRINT_PERIODIC_STATS
		atomic_inc(&s_sample_count);
		const int64_t now_ms = k_uptime_get();
		if (now_ms >= s_next_report_ms)
		{
			printk("IMU: data_ready_count=%d sample_count=%d not_acquired=%d\n", 
				(int)atomic_set(&s_data_ready_count, 0), 
				(int)atomic_set(&s_sample_count, 0), 
				(int)atomic_set(&s_not_acquired_count, 0));
			s_next_report_ms = now_ms + CONFIG_IM_IMU_STATS_PERIOD_MS;
		}
#endif
	}
}

static bool s_imu_wait_ready(void)
{
	// The driver init fails, if the chip does not ACK, probe I2C first
	uint8_t who_am_i;
	if (!i2c_is_ready_dt(&s_i2c_bus))
	{
		printk("Error: IMU I2C bus is not ready\n");
		return false;
	}
	const int64_t start = k_uptime_get();
	while (i2c_reg_read_byte_dt(&s_i2c_bus, IMU_REG_WHO_AM_I, &who_am_i) < 0)
	{
		if (k_uptime_get() - start > IMU_READY_TIMEOUT_MS)
		{
			printk("Error: IMU does not respond on I2C\n");
			return false;
		}
		k_msleep(IMU_READY_POLL_MS);
	}
	printk("IMU responded on I2C after %d ms, who_am_i=0x%x\n", (int)(k_uptime_get() - start), who_am_i);
	return true;
}

// External linkage

void im_imu_set_sample_cb(im_imu_sample_cb_t cb)
{
	s_sample_cb = cb;
}

void im_imu_set_error_callback(im_imu_error_cb_t cb)
{
	s_error_cb = cb;
}

void im_imu_set_streaming(bool enabled)
{
	// Give the semaphore to cycle the thread
	// Bool flag will control the IMU device init/deinit
	if (enabled)
	{
		if (atomic_cas(&s_streaming_requested, 0, 1))
		{
			k_sem_give(&s_imu_data_ready);
		}
	}
	else
	{
		if (atomic_cas(&s_streaming_requested, 1, 0))
		{
			k_sem_give(&s_imu_data_ready);
		}
	}
}

bool im_imu_thread_start()
{
	static const struct sensor_trigger trig =
	{
		.type = SENSOR_TRIG_DATA_READY,
		.chan = SENSOR_CHAN_ACCEL_XYZ,
	};
	if (sensor_trigger_set(s_imu, &trig, s_imu_data_ready_handler) < 0)
	{
		printk("Error: IMU Cannot set data ready trigger\n");
		return false;
	}
	k_tid_t tid = k_thread_create(&s_imu_thread_data, s_imu_thread_stack,
				      K_THREAD_STACK_SIZEOF(s_imu_thread_stack),
				      s_imu_thread_fn, NULL, NULL, NULL,
				      IM_IMU_THREAD_PRIORITY, IM_IMU_THREAD_OPTIONS, K_NO_WAIT);
	k_thread_name_set(tid, "imu");
	return true;
}

bool im_imu_init()
{
	if (!s_imu) 
	{
        printk("Error: IMU device pointer not found\n");
        return false;
    }
	// Delayed init - normal (OS) init does not work (I2C powerline not ready)
	if (!s_imu_wait_ready())
	{
		return false;
	}
	printk("IMU Manual delayed initialization\n");
    const int err = device_init(s_imu);
    if (err)
	{
      	printk("Error: I2C initialization failed, error code: %d\n", err);
    	return false;
    }
	if(!device_is_ready(s_imu)) 
	{
		const uint8_t state = s_imu->state->init_res;
		const bool initialized = s_imu->state->initialized;
		printk("Error: IMU not ready, init_res=%d init=%d\n", state, initialized);
		return false;
	}
	printk("IMU stopping sampling until BLE session starts\n");
	if (!s_imu_set_sampling_frequency(0))
	{
		return false;
	}
	printk("IMU Ok\n");
	return true;
}
```

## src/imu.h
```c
#ifndef IM_IMU_H
#define IM_IMU_H

#include <stdbool.h>
#include "math3d.h"

/* Called with gyro rates in rad/s, acceleration in m/s^2, and elapsed time in seconds. */
typedef void (*im_imu_sample_cb_t)(im_vec3 gyro_rate, im_vec3 acceleration, float dt_s);
typedef void (*im_imu_error_cb_t)(void);

void im_imu_set_sample_cb(im_imu_sample_cb_t cb);
void im_imu_set_error_callback(im_imu_error_cb_t cb);
/* Requests streaming; the IMU thread applies ODR and trigger changes asynchronously. */
void im_imu_set_streaming(bool enabled);
bool im_imu_thread_start(void);
bool im_imu_init();

#endif
```

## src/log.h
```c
#ifndef IM_LOG_H
#define IM_LOG_H

void im_log_thread_start(void);

#endif
```

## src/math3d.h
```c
#ifndef IM_MATH3D_H
#define IM_MATH3D_H

#include <math.h>
#include <stdbool.h>

typedef struct
{
	float x;
	float y;
	float z;
} im_vec3;

/* Unit quaternions actively rotate vectors from a source frame to a destination frame. */
typedef struct
{
	float w;
	float x;
	float y;
	float z;
} im_quat;

static inline im_vec3 im_vec3_add(im_vec3 a, im_vec3 b)
{
	return (im_vec3){a.x + b.x, a.y + b.y, a.z + b.z};
}

static inline im_vec3 im_vec3_subtract(im_vec3 a, im_vec3 b)
{
	return (im_vec3){a.x - b.x, a.y - b.y, a.z - b.z};
}

static inline im_vec3 im_vec3_scale(im_vec3 value, float scale)
{
	return (im_vec3){value.x * scale, value.y * scale, value.z * scale};
}

static inline float im_vec3_dot(im_vec3 a, im_vec3 b)
{
	return a.x * b.x + a.y * b.y + a.z * b.z;
}

static inline im_vec3 im_vec3_cross(im_vec3 a, im_vec3 b)
{
	return (im_vec3){a.y * b.z - a.z * b.y, a.z * b.x - a.x * b.z, a.x * b.y - a.y * b.x};
}

static inline float im_vec3_length(im_vec3 value)
{
	return sqrtf(im_vec3_dot(value, value));
}

static inline bool im_vec3_normalize(im_vec3 *value)
{
	const float length = im_vec3_length(*value);
	if (length < 1e-6f)
	{
		return false;
	}
	*value = im_vec3_scale(*value, 1.0f / length);
	return true;
}

static inline im_quat im_quat_identity(void)
{
	return (im_quat){1.0f, 0.0f, 0.0f, 0.0f};
}

static inline im_quat im_quat_add(im_quat a, im_quat b)
{
	return (im_quat){a.w + b.w, a.x + b.x, a.y + b.y, a.z + b.z};
}

static inline im_quat im_quat_scale(im_quat value, float scale)
{
	return (im_quat){value.w * scale, value.x * scale, value.y * scale, value.z * scale};
}

static inline im_quat im_quat_multiply(im_quat a, im_quat b)
{
	return (im_quat){
		a.w * b.w - a.x * b.x - a.y * b.y - a.z * b.z,
		a.w * b.x + a.x * b.w + a.y * b.z - a.z * b.y,
		a.w * b.y - a.x * b.z + a.y * b.w + a.z * b.x,
		a.w * b.z + a.x * b.y - a.y * b.x + a.z * b.w};
}

static inline im_quat im_quat_conjugate(im_quat value)
{
	return (im_quat){value.w, -value.x, -value.y, -value.z};
}

static inline bool im_quat_normalize(im_quat *value)
{
	const float norm = sqrtf(value->w * value->w + value->x * value->x + value->y * value->y + value->z * value->z);
	if (norm < 1e-6f)
	{
		return false;
	}
	const float inverse_norm = 1.0f / norm;
	*value = im_quat_scale(*value, inverse_norm);
	return true;
}

static inline im_quat im_quat_from_unit_vectors(im_vec3 from, im_vec3 to)
{
	const float dot = im_vec3_dot(from, to);
	if (dot < -0.999999f)
	{
		const im_vec3 basis = fabsf(from.x) < 0.9f ? (im_vec3){1.0f, 0.0f, 0.0f} : (im_vec3){0.0f, 1.0f, 0.0f};
		im_vec3 axis = im_vec3_cross(from, basis);
		im_vec3_normalize(&axis);
		return (im_quat){0.0f, axis.x, axis.y, axis.z};
	}

	const im_vec3 axis = im_vec3_cross(from, to);
	im_quat result = {1.0f + dot, axis.x, axis.y, axis.z};
	im_quat_normalize(&result);
	return result;
}

static inline im_vec3 im_quat_rotate(im_quat rotation, im_vec3 value)
{
	const im_vec3 vector = {rotation.x, rotation.y, rotation.z};
	const im_vec3 twice_cross = im_vec3_scale(im_vec3_cross(vector, value), 2.0f);
	return im_vec3_add(value, im_vec3_add(im_vec3_scale(twice_cross, rotation.w), im_vec3_cross(vector, twice_cross)));
}

static inline im_vec3 im_quat_rotate_inverse(im_quat rotation, im_vec3 value)
{
	return im_quat_rotate(im_quat_conjugate(rotation), value);
}

#endif
```

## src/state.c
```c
#include <zephyr/kernel.h>

#include "state.h"

static atomic_t s_state = ATOMIC_INIT(IM_APP_STATE_INIT_1);

enum im_app_state im_state_get(void)
{
	return (enum im_app_state)atomic_get(&s_state);
}

void im_state_set(enum im_app_state state)
{
	atomic_set(&s_state, (atomic_val_t)state);
	printk("Entering state: %d\n", state);
}
```

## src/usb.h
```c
#ifndef IM_USB_H
#define IM_USB_H

bool im_usb_init(void);

#endif
```
